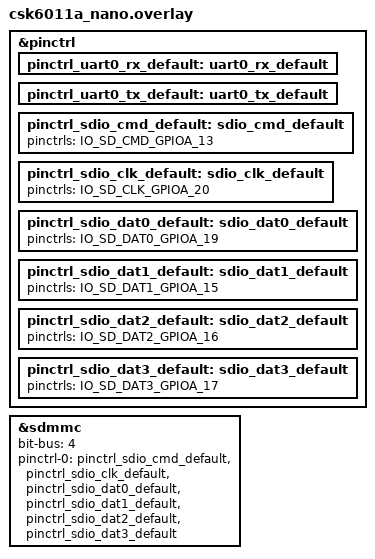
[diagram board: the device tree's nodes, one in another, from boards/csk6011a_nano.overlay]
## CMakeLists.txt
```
# SPDX-License-Identifier: Apache-2.0

cmake_minimum_required(VERSION 3.20.0)

set(SUPPORT_BOARDS csk6012_nano csk6011a_nano)
if(NOT ${BOARD} IN_LIST SUPPORT_BOARDS)
    message("Please choose one of the following boards:")
    foreach(item ${SUPPORT_BOARDS})
        message(STATUS ${item})
    endforeach()
    message(FATAL_ERROR "\nThe project does not support the ${BOARD}")
endif()

find_package(Zephyr REQUIRED HINTS $ENV{ZEPHYR_BASE})
project(sdmmc)

target_sources(app PRIVATE src/main.c)
```

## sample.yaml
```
tests:
  sample.board.csk6.driver.sdmmc:
    platform_allow: csk6011a_nano
    tags: csk6
    build_only: true
```

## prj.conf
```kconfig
CONFIG_DISK_ACCESS=y
CONFIG_DISK_DRIVER_SDMMC=y
CONFIG_LOG=y
CONFIG_LOG_MODE_IMMEDIATE=y
CONFIG_HEAP_MEM_POOL_SIZE=20000
CONFIG_SDMMC_NON_BLOCK_INIT=y
```

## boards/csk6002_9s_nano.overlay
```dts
/*
 * SPDX-License-Identifier: Apache-2.0
 */

&pinctrl{
    /* UART alternate function */
    pinctrl_uart0_rx_default: uart0_rx_default{
    };
    
    pinctrl_uart0_tx_default: uart0_tx_default{
        pinctrls = <UART0_TXD_GPIOB_01>;
    };
    
    /* SDIO alternate function */
    pinctrl_sdio_cmd_default: sdio_cmd_default{
        pinctrls = <IO_SD_CMD_GPIOB_07>;
    };
    
    pinctrl_sdio_clk_default: sdio_clk_default{
        pinctrls = <IO_SD_CLK_GPIOB_08>;
    };

    pinctrl_sdio_dat0_default: sdio_dat0_default{
        pinctrls = <IO_SD_DAT0_GPIOB_06>;
    };

    pinctrl_sdio_dat1_default: sdio_dat1_default{
        pinctrls = <IO_SD_DAT1_GPIOA_02>;
    };

    pinctrl_sdio_dat2_default: sdio_dat2_default{
        pinctrls = <IO_SD_DAT2_GPIOB_04>;
    };

    pinctrl_sdio_dat3_default: sdio_dat3_default{
        pinctrls = <IO_SD_DAT3_GPIOB_09>;
    };
};
```

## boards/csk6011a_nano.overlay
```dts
/*
 * Copyright (c) 2023 Anhui(Shenzhen) Listenai Co., Ltd.
 *
 * SPDX-License-Identifier: Apache-2.0
 */
&pinctrl {
	/* UART alternate function */
	pinctrl_uart0_rx_default: uart0_rx_default{
	};

	pinctrl_uart0_tx_default: uart0_tx_default{
	};

	/* SDIO alternate function */
	pinctrl_sdio_cmd_default: sdio_cmd_default{
		pinctrls = <IO_SD_CMD_GPIOA_13>;
	};

	pinctrl_sdio_clk_default: sdio_clk_default{
		pinctrls = <IO_SD_CLK_GPIOA_20>;
	};

	pinctrl_sdio_dat0_default: sdio_dat0_default{
		pinctrls = <IO_SD_DAT0_GPIOA_19>;
	};

	pinctrl_sdio_dat1_default: sdio_dat1_default{
		pinctrls = <IO_SD_DAT1_GPIOA_15>;
	};

	pinctrl_sdio_dat2_default: sdio_dat2_default{
		pinctrls = <IO_SD_DAT2_GPIOA_16>;
	};

	pinctrl_sdio_dat3_default: sdio_dat3_default{
		pinctrls = <IO_SD_DAT3_GPIOA_17>;
	};
};

&sdmmc {
	status = "okay";
	bit-bus = <4>;
	pinctrl-0 = <
	&pinctrl_sdio_cmd_default
	&pinctrl_sdio_clk_default
	&pinctrl_sdio_dat0_default
	&pinctrl_sdio_dat1_default
	&pinctrl_sdio_dat2_default
	&pinctrl_sdio_dat3_default
	>;
	pinctrl-names = "default";
};
```

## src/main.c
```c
/*
 * Copyright (c) 2023 Anhui(Shenzhen) Listenai Co., Ltd.
 *
 * SPDX-License-Identifier: Apache-2.0
 */

#include <stdlib.h>

#include <zephyr/device.h>
#include <zephyr/storage/disk_access.h>
#include <zephyr/zephyr.h>

#include <logging/log.h>
LOG_MODULE_REGISTER(sample, LOG_LEVEL_DBG);

#define NUM_SECTORS (1U)
static const char *disk_pdrv = CONFIG_SDMMC_VOLUME_NAME;
static uint32_t disk_sector_count;
static uint32_t disk_sector_size;
static uint8_t *wbuf, *rbuf;

void main(void)
{
	int ret = 0;
	uint32_t cmd_buf;

	ret = disk_access_init(disk_pdrv);

	ret = disk_access_ioctl(disk_pdrv, DISK_IOCTL_GET_SECTOR_COUNT, &cmd_buf);
	if (ret != 0) {
		LOG_ERR("Disk ioctl get sector count failed (%d)\n", ret);
		return;
	}

	disk_sector_count = cmd_buf;
	LOG_DBG("Disk reports %u sectors\n", cmd_buf);

	ret = disk_access_ioctl(disk_pdrv, DISK_IOCTL_GET_SECTOR_SIZE, &cmd_buf);
	if (ret != 0) {
		LOG_ERR("Disk ioctl get sector size failed (%d)\n", ret);
		return;
	}

	disk_sector_size = cmd_buf;
	LOG_DBG("Disk reports sector size %u\n", cmd_buf);

	wbuf = (uint8_t *)k_malloc(NUM_SECTORS * disk_sector_size);
	if (wbuf == NULL) {
		LOG_ERR(" wbuf malloc failed\n");
	}

	for (uint32_t i = 0; i < NUM_SECTORS * disk_sector_size; i++) {
		wbuf[i] = i;
	}

	LOG_HEXDUMP_INF(wbuf, 256, "wbuf");

	ret = disk_access_write(disk_pdrv, wbuf, 1, NUM_SECTORS);
	if (ret) {
		LOG_ERR("disk_access_write failed (%d)\n", ret);
		return;
	}

	rbuf = (uint8_t *)k_malloc(NUM_SECTORS * disk_sector_size);
	if (rbuf == NULL) {
		LOG_ERR(" rbuf malloc failed\n");
	}
	memset(rbuf, 0, NUM_SECTORS * disk_sector_size);

	ret = disk_access_read(disk_pdrv, rbuf, 1, NUM_SECTORS);
	if (ret) {
		LOG_ERR("disk_access_write failed (%d)\n", ret);
		return;
	}

	LOG_HEXDUMP_INF(rbuf, 256, "rbuf");

	for (uint32_t i = 0; i < NUM_SECTORS * disk_sector_size; i++) {
		if (rbuf[i] != wbuf[i]) {
			LOG_ERR("Read data did not match data written to disk %d\n", i);
			return;
		}
	}

	LOG_DBG("sdcard sample done \n");
}
```
